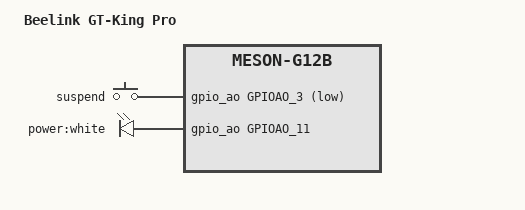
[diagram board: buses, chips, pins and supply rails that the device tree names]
// SPDX-License-Identifier: (GPL-2.0+ OR MIT)
/*
 * Copyright (c) 2019 BayLibre, SAS
 * Author: Neil Armstrong <narmstrong@baylibre.com>
 * Copyright (c) 2019 Christian Hewitt <christianshewitt@gmail.com>
 */

/dts-v1/;

#include "meson-g12b-w400.dtsi"
#include "meson-g12-audio-hdmi.dtsi"

/ {
	compatible = "azw,gtking", "amlogic,g12b";
	model = "Beelink GT-King Pro";

	gpio-keys-polled {
		compatible = "gpio-keys-polled";
		#address-cells = <1>;
		#size-cells = <0>;
		poll-interval = <100>;

		power-button {
			label = "suspend";
			linux,code = <KEY_POWER>;
			gpios = <&gpio_ao GPIOAO_3 GPIO_ACTIVE_LOW>;
		};
	};

	leds {
		compatible = "gpio-leds";

		white {
			label = "power:white";
			gpios = <&gpio_ao GPIOAO_11 GPIO_ACTIVE_HIGH>;
			default-state = "on";
		};
	};
};
